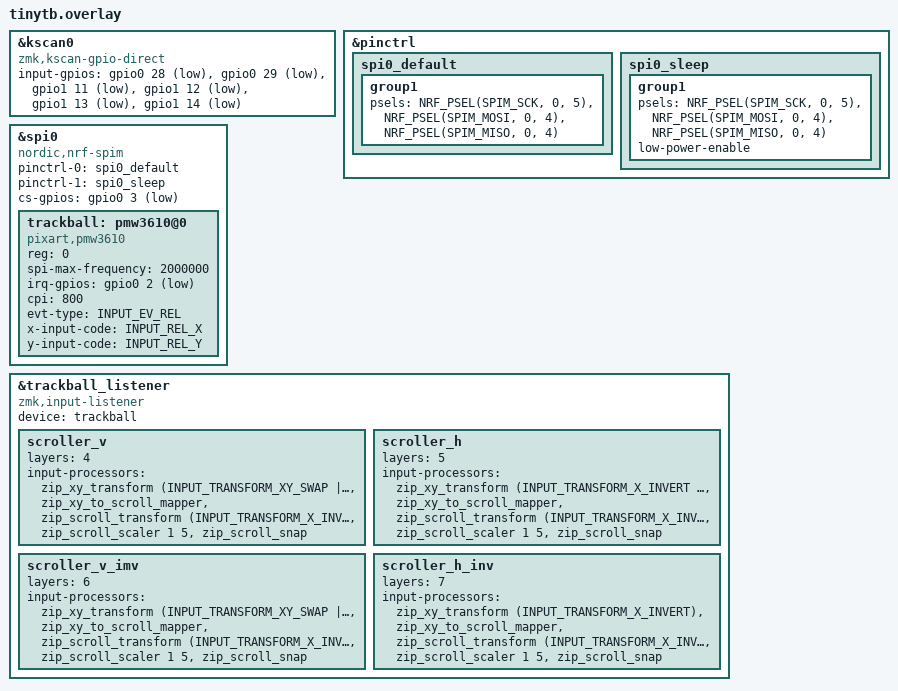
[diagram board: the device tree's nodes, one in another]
#include "tinytb.dtsi"
#include <input/processors.dtsi>
#include <zephyr/dt-bindings/input/input-event-codes.h>
#include <dt-bindings/zmk/input_transform.h>

&kscan0 {
        compatible = "zmk,kscan-gpio-direct";
        input-gpios =
            <&gpio0 28 (GPIO_ACTIVE_LOW | GPIO_PULL_UP)>,
            <&gpio0 29 (GPIO_ACTIVE_LOW | GPIO_PULL_UP)>,
            <&gpio1 11 (GPIO_ACTIVE_LOW | GPIO_PULL_UP)>,
            <&gpio1 12 (GPIO_ACTIVE_LOW | GPIO_PULL_UP)>,
            <&gpio1 13 (GPIO_ACTIVE_LOW | GPIO_PULL_UP)>,
            <&gpio1 14 (GPIO_ACTIVE_LOW | GPIO_PULL_UP)>;
    };


&pinctrl {
    spi0_default: spi0_default {
        group1 {
            psels = <NRF_PSEL(SPIM_SCK, 0, 5)>,
                    <NRF_PSEL(SPIM_MOSI, 0, 4)>,
                    <NRF_PSEL(SPIM_MISO, 0, 4)>;
        };
    };

    spi0_sleep: spi0_sleep {
        group1 {
            psels = <NRF_PSEL(SPIM_SCK, 0, 5)>,
                    <NRF_PSEL(SPIM_MOSI, 0, 4)>,
                    <NRF_PSEL(SPIM_MISO, 0, 4)>;
            low-power-enable;
        };
    };
};

&spi0 {
    status = "okay";
    compatible = "nordic,nrf-spim";
    pinctrl-0 = <&spi0_default>;
    pinctrl-1 = <&spi0_sleep>;
    pinctrl-names = "default", "sleep";
    cs-gpios = <&gpio0 3 GPIO_ACTIVE_LOW>;

    trackball: pmw3610@0 {
        status = "okay";
        compatible = "pixart,pmw3610";
        reg = <0>;
        spi-max-frequency = <2000000>;
        irq-gpios = <&gpio0 2 (GPIO_ACTIVE_LOW | GPIO_PULL_UP)>;
        cpi = <800>;
        evt-type = <INPUT_EV_REL>;
        x-input-code = <INPUT_REL_X>;
        y-input-code = <INPUT_REL_Y>;
    };
};

&trackball_listener {
    compatible = "zmk,input-listener";
    status = "okay";
    device = <&trackball>;

    /* L1 = 4: 縦スクロール */
    scroller_v {
      layers = <4>;
      input-processors =
        <&zip_xy_transform (INPUT_TRANSFORM_XY_SWAP | INPUT_TRANSFORM_X_INVERT | INPUT_TRANSFORM_Y_INVERT)>, /* ←必要な回転/反転は1行に集約 or 必要なだけ */
        <&zip_xy_to_scroll_mapper>,
        <&zip_scroll_transform (INPUT_TRANSFORM_X_INVERT)>,  /* 必要なら反転。不要なら消す */
        <&zip_scroll_scaler 1 5>,                             /* 1/2倍なら 1 2 */
        <&zip_scroll_snap>;
    };

    /* L2 = 5: 横スクロール */
    scroller_h {
      layers = <5>;
      input-processors =
        <&zip_xy_transform (INPUT_TRANSFORM_X_INVERT | INPUT_TRANSFORM_Y_INVERT)>,
        <&zip_xy_to_scroll_mapper>,
        <&zip_scroll_transform (INPUT_TRANSFORM_X_INVERT)>,
        <&zip_scroll_scaler 1 5>,
        <&zip_scroll_snap>;
    };

    /* L3 = 6: 縦スクロール（逆） */
    scroller_v_imv {
      layers = <6>;
      input-processors =
        <&zip_xy_transform (INPUT_TRANSFORM_XY_SWAP | INPUT_TRANSFORM_X_INVERT)>, /* ←必要な回転/反転は1行に集約 or 必要なだけ */
        <&zip_xy_to_scroll_mapper>,
        <&zip_scroll_transform (INPUT_TRANSFORM_X_INVERT)>,  /* 必要なら反転。不要なら消す */
        <&zip_scroll_scaler 1 5>,                             /* 1/2倍なら 1 2 */
        <&zip_scroll_snap>;
    };

    /* L4 = 7: 横スクロール（逆） */
    scroller_h_inv {
      layers = <7>;
      input-processors =
        <&zip_xy_transform (INPUT_TRANSFORM_X_INVERT)>,
        <&zip_xy_to_scroll_mapper>,
        <&zip_scroll_transform (INPUT_TRANSFORM_X_INVERT)>,
        <&zip_scroll_scaler 1 5>,
        <&zip_scroll_snap>;
    };
};















